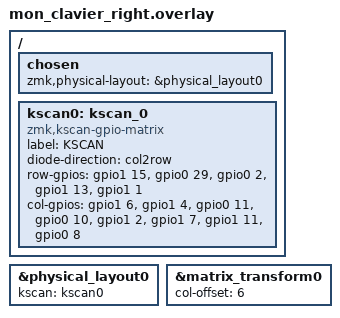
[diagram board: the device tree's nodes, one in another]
#include "mon_clavier.dtsi"

/ {
    chosen {
        /* Même punition pour la moitié droite : que le physical-layout */
        zmk,physical-layout = &physical_layout0;
    };

    kscan0: kscan_0 {
        compatible = "zmk,kscan-gpio-matrix";
        label = "KSCAN";
        diode-direction = "col2row";

        row-gpios
            = <&gpio1 15 (GPIO_ACTIVE_HIGH | GPIO_PULL_DOWN)> /* ROW0 */
            , <&gpio0 29 (GPIO_ACTIVE_HIGH | GPIO_PULL_DOWN)> /* ROW1 */
            , <&gpio0  2 (GPIO_ACTIVE_HIGH | GPIO_PULL_DOWN)> /* ROW2 */
            , <&gpio1 13 (GPIO_ACTIVE_HIGH | GPIO_PULL_DOWN)> /* ROW3 */
            , <&gpio1  1 (GPIO_ACTIVE_HIGH | GPIO_PULL_DOWN)> /* ROW4 */
            ;

        col-gpios
            = <&gpio1  6 GPIO_ACTIVE_HIGH> /* COL0 */
            , <&gpio1  4 GPIO_ACTIVE_HIGH> /* COL1 */
            , <&gpio0 11 GPIO_ACTIVE_HIGH> /* COL2 */
            , <&gpio0 10 GPIO_ACTIVE_HIGH> /* COL3 */
            , <&gpio1  2 GPIO_ACTIVE_HIGH> /* COL4 */
            , <&gpio1 7 GPIO_ACTIVE_HIGH> /* COL5 */
            , <&gpio1 11 GPIO_ACTIVE_HIGH> /* COL6 */
            , <&gpio0  8 GPIO_ACTIVE_HIGH> /* COL7 */
            ;
    };
};

/* On attache le kscan de droite au layout physique */
&physical_layout0 {
    kscan = <&kscan0>;
};

&matrix_transform0 {
    col-offset = <6>; /* Le côté gauche a 6 colonnes (0 à 5), le côté droit commence à la colonne 6 */
};
